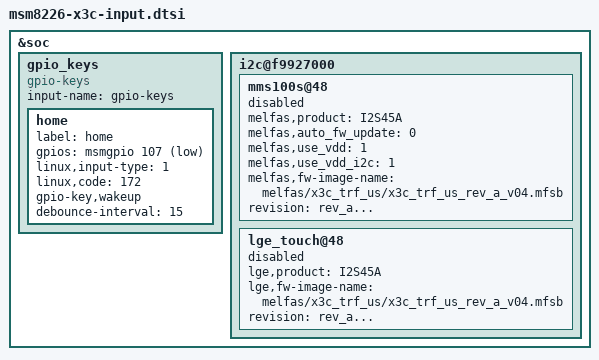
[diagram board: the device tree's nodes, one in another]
/* Copyright (c) 2013, LGE Electronics. All rights reserved.
 *
 * This program is free software; you can redistribute it and/or modify
 * it under the terms of the GNU General Public License version 2 and
 * only version 2 as published by the Free Software Foundation.
 *
 * This program is distributed in the hope that it will be useful,
 * but WITHOUT ANY WARRANTY; without even the implied warranty of
 * MERCHANTABILITY or FITNESS FOR A PARTICULAR PURPOSE.  See the
 * GNU General Public License for more details.
 */

&soc {

	gpio_keys {
		compatible = "gpio-keys";
		input-name = "gpio-keys";

		home {
			label = "home";
			gpios = <&msmgpio 107 0x1>;
			linux,input-type = <1>;
			linux,code = <172>;
			gpio-key,wakeup;
			debounce-interval = <15>;
		};
	};
	
	i2c@f9927000 { /* BLSP1 QUP5 */
		mms100s@48 {
			melfas,product = "I2S45A";
			melfas,auto_fw_update = <0>;
			melfas,use_vdd = <1>;
			melfas,use_vdd_i2c = <1>;
			melfas,fw-image-name = "melfas/x3c_trf_us/x3c_trf_us_rev_a_v04.mfsb";
			revision = "rev_a...";
			status = "disable";
		};

		lge_touch@48 {
			lge,product = "I2S45A";
			lge,fw-image-name = "melfas/x3c_trf_us/x3c_trf_us_rev_a_v04.mfsb";
			revision = "rev_a...";
			status = "disable";
		};
	};

};
